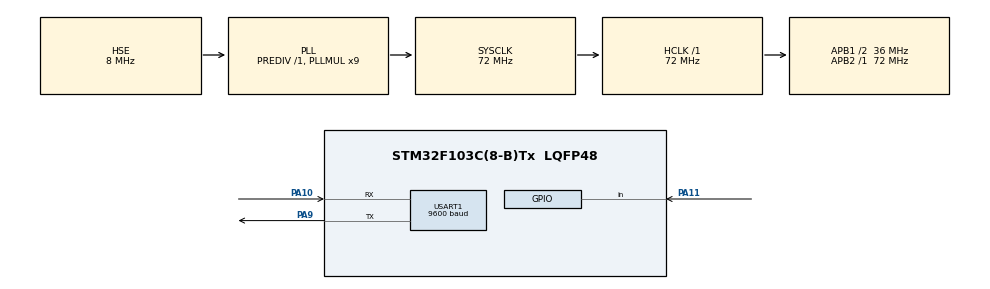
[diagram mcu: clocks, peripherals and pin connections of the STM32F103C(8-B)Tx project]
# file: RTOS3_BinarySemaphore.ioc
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FREERTOS.BinarySemaphores01=BinarySem,Dynamic,NULL
FREERTOS.Tasks01=Task1,-1,128,StartTask1,Default,NULL,Dynamic,NULL,NULL;Task2,0,128,StartTask2,Default,NULL,Dynamic,NULL,NULL;Task3,1,128,StartTask3,Default,NULL,Dynamic,NULL,NULL
Mcu.Family=STM32F1
Mcu.Name=STM32F103C(8-B)Tx
Mcu.Package=LQFP48
NVIC.PriorityGroup=NVIC_PRIORITYGROUP_4
NVIC.TIM1_UP_IRQn=true\:0\:0\:false\:false\:true\:false\:false\:true
NVIC.TimeBase=TIM1_UP_IRQn
NVIC.TimeBaseIP=TIM1
PA10.Mode=Asynchronous
PA10.Signal=USART1_RX
PA11.GPIO_PuPd=GPIO_NOPULL
PA11.Signal=GPIO_Input
PA13.Mode=Serial_Wire
PA13.Signal=SYS_JTMS-SWDIO
PA14.Mode=Serial_Wire
PA14.Signal=SYS_JTCK-SWCLK
PA9.Mode=Asynchronous
PA9.Signal=USART1_TX
PD0-OSC_IN.Mode=HSE-External-Oscillator
PD0-OSC_IN.Signal=RCC_OSC_IN
PD1-OSC_OUT.Mode=HSE-External-Oscillator
PD1-OSC_OUT.Signal=RCC_OSC_OUT
ProjectManager.HeapSize=0x200
ProjectManager.StackSize=0x400
ProjectManager.TargetToolchain=MDK-ARM V5.27
RCC.AHBFreq_Value=72000000
RCC.APB1CLKDivider=RCC_HCLK_DIV2
RCC.APB1Freq_Value=36000000
RCC.APB1TimFreq_Value=72000000
RCC.APB2Freq_Value=72000000
RCC.APB2TimFreq_Value=72000000
RCC.HCLKFreq_Value=72000000
RCC.PLLMUL=RCC_PLL_MUL9
RCC.PLLSourceVirtual=RCC_PLLSOURCE_HSE
RCC.SYSCLKFreq_VALUE=72000000
RCC.SYSCLKSource=RCC_SYSCLKSOURCE_PLLCLK
RCC.USBFreq_Value=72000000
USART1.BaudRate=9600
USART1.VirtualMode=VM_ASYNC
VP_FREERTOS_VS_CMSIS_V1.Mode=CMSIS_V1
VP_SYS_VS_tim1.Mode=TIM1
board=custom

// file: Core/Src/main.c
/* USER CODE BEGIN Header */
/**
  ******************************************************************************
  * @file           : main.c
  * @brief          : Main program body
  ******************************************************************************
  * @attention
  *
  * <h2><center>&copy; Copyright (c) 2020 STMicroelectronics.
  * All rights reserved.</center></h2>
  *
  * This software component is licensed by ST under Ultimate Liberty license
  * SLA0044, the "License"; You may not use this file except in compliance with
  * the License. You may obtain a copy of the License at:
  *                             www.st.com/SLA0044
  *
  ******************************************************************************
  */
/* USER CODE END Header */
#include "main.h"
#include "cmsis_os.h"
#include "stdio.h"
#include "string.h"

UART_HandleTypeDef huart1;

osThreadId Task1Handle;
osThreadId Task2Handle;
osThreadId Task3Handle;
osSemaphoreId BinarySemHandle;

void SystemClock_Config(void);
static void MX_GPIO_Init(void);
static void MX_USART1_UART_Init(void);
void StartTask1(void const * argument);
void StartTask2(void const * argument);
void StartTask3(void const * argument);

int main(void)
{

  /* MCU Configuration--------------------------------------------------------*/

  /* Reset of all peripherals, Initializes the Flash interface and the Systick. */
  HAL_Init();

  /* Configure the system clock */
  SystemClock_Config();

  /* Initialize all configured peripherals */
  MX_GPIO_Init();
  MX_USART1_UART_Init();

  /* Create the semaphores(s) */
  /* definition and creation of BinarySem */
  osSemaphoreDef(BinarySem);
  BinarySemHandle = osSemaphoreCreate(osSemaphore(BinarySem), 1);

  /* Create the thread(s) */
  /* definition and creation of Task1 */
  osThreadDef(Task1, StartTask1, osPriorityBelowNormal, 0, 128);
  Task1Handle = osThreadCreate(osThread(Task1), NULL);

  /* definition and creation of Task2 */
  osThreadDef(Task2, StartTask2, osPriorityNormal, 0, 128);
  Task2Handle = osThreadCreate(osThread(Task2), NULL);

  /* definition and creation of Task3 */
  osThreadDef(Task3, StartTask3, osPriorityAboveNormal, 0, 128);
  Task3Handle = osThreadCreate(osThread(Task3), NULL);

  /* Start scheduler */
  osKernelStart();

  /* We should never get here as control is now taken by the scheduler */
  /* Infinite loop */
  while (1)
  {

  }
}

void SystemClock_Config(void)
{
  RCC_OscInitTypeDef RCC_OscInitStruct = {0};
  RCC_ClkInitTypeDef RCC_ClkInitStruct = {0};

  /** Initializes the RCC Oscillators according to the specified parameters
  * in the RCC_OscInitTypeDef structure.
  */
  RCC_OscInitStruct.OscillatorType = RCC_OSCILLATORTYPE_HSE;
  RCC_OscInitStruct.HSEState = RCC_HSE_ON;
  RCC_OscInitStruct.HSEPredivValue = RCC_HSE_PREDIV_DIV1;
  RCC_OscInitStruct.HSIState = RCC_HSI_ON;
  RCC_OscInitStruct.PLL.PLLState = RCC_PLL_ON;
  RCC_OscInitStruct.PLL.PLLSource = RCC_PLLSOURCE_HSE;
  RCC_OscInitStruct.PLL.PLLMUL = RCC_PLL_MUL9;
  if (HAL_RCC_OscConfig(&RCC_OscInitStruct) != HAL_OK)
  {
    Error_Handler();
  }
  /** Initializes the CPU, AHB and APB buses clocks
  */
  RCC_ClkInitStruct.ClockType = RCC_CLOCKTYPE_HCLK|RCC_CLOCKTYPE_SYSCLK
                              |RCC_CLOCKTYPE_PCLK1|RCC_CLOCKTYPE_PCLK2;
  RCC_ClkInitStruct.SYSCLKSource = RCC_SYSCLKSOURCE_PLLCLK;
  RCC_ClkInitStruct.AHBCLKDivider = RCC_SYSCLK_DIV1;
  RCC_ClkInitStruct.APB1CLKDivider = RCC_HCLK_DIV2;
  RCC_ClkInitStruct.APB2CLKDivider = RCC_HCLK_DIV1;

  if (HAL_RCC_ClockConfig(&RCC_ClkInitStruct, FLASH_LATENCY_2) != HAL_OK)
  {
    Error_Handler();
  }
}

static void MX_USART1_UART_Init(void)
{

  huart1.Instance = USART1;
  huart1.Init.BaudRate = 9600;
  huart1.Init.WordLength = UART_WORDLENGTH_8B;
  huart1.Init.StopBits = UART_STOPBITS_1;
  huart1.Init.Parity = UART_PARITY_NONE;
  huart1.Init.Mode = UART_MODE_TX_RX;
  huart1.Init.HwFlowCtl = UART_HWCONTROL_NONE;
  huart1.Init.OverSampling = UART_OVERSAMPLING_16;
  if (HAL_UART_Init(&huart1) != HAL_OK)
  {
    Error_Handler();
  }

}

static void MX_GPIO_Init(void)
{
  GPIO_InitTypeDef GPIO_InitStruct = {0};

  /* GPIO Ports Clock Enable */
  __HAL_RCC_GPIOD_CLK_ENABLE();
  __HAL_RCC_GPIOA_CLK_ENABLE();

  /*Configure GPIO pin : PA11 */
  GPIO_InitStruct.Pin = GPIO_PIN_11;
  GPIO_InitStruct.Mode = GPIO_MODE_INPUT;
  GPIO_InitStruct.Pull = GPIO_PULLUP;
  HAL_GPIO_Init(GPIOA, &GPIO_InitStruct);

}

void StartTask1(void const * argument)
{
  /* USER CODE BEGIN 5 */
  char *pcTransmitString1 = "Entered Task 1 and waiting for Semaphore\r\n";
  char *pcTransmitString2 = "Semaphore acquired by Task 1\r\n";
  char *pcTransmitString3 = "Leaving task 1 and releasing Semapore\r\n\r\n";
  /* Infinite loop */
  for(;;)
  {
    HAL_UART_Transmit(&huart1, (uint8_t *)pcTransmitString1, strlen(pcTransmitString1), 200);
    osSemaphoreWait(BinarySemHandle, osWaitForever);
    HAL_UART_Transmit(&huart1, (uint8_t *)pcTransmitString2, strlen(pcTransmitString2), 200);
    while (HAL_GPIO_ReadPin(GPIOA, GPIO_PIN_11) !=0);

    HAL_UART_Transmit(&huart1, (uint8_t *)pcTransmitString3, strlen(pcTransmitString3), 200);
    osSemaphoreRelease(BinarySemHandle);
    osDelay(500);
  }
  /* USER CODE END 5 */
}

void StartTask2(void const * argument)
{
  /* USER CODE BEGIN StartTask2 */
  char *pcTransmitString1 = "Entered Task 2\r\n";
  char *pcTransmitString2 = "Leaving Task 2\r\n\r\n";
  /* Infinite loop */
  for(;;)
  {
    HAL_UART_Transmit(&huart1, (uint8_t *)pcTransmitString1, strlen(pcTransmitString1), 200);
    HAL_UART_Transmit(&huart1, (uint8_t *)pcTransmitString2, strlen(pcTransmitString2), 200);
    osDelay(500);
  }
  /* USER CODE END StartTask2 */
}

void StartTask3(void const * argument)
{
  /* USER CODE BEGIN StartTask3 */
  char *pcTransmitString1 = "Entered Task 3 and waiting for Semaphore\r\n";
  char *pcTransmitString2 = "Semaphore acquired by Task 3\r\n";
  char *pcTransmitString3 = "Leaving task 3 and releasing Semapore\r\n\r\n";
  /* Infinite loop */
  for(;;)
  {
    HAL_UART_Transmit(&huart1, (uint8_t *)pcTransmitString1, strlen(pcTransmitString1),200);
    osSemaphoreWait(BinarySemHandle, osWaitForever);
    HAL_UART_Transmit(&huart1, (uint8_t *)pcTransmitString2, strlen(pcTransmitString2), 200);
    HAL_UART_Transmit(&huart1, (uint8_t *)pcTransmitString3, strlen(pcTransmitString3), 200);
    osSemaphoreRelease(BinarySemHandle);
    osDelay(500);
  }
  /* USER CODE END StartTask3 */
}

void HAL_TIM_PeriodElapsedCallback(TIM_HandleTypeDef *htim)
{
  if (htim->Instance == TIM1) {
    HAL_IncTick();
  }
}

void Error_Handler(void)
{
}

/************************ (C) COPYRIGHT STMicroelectronics *****END OF FILE****/
